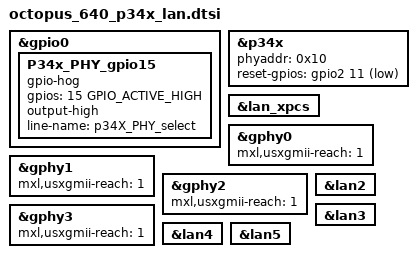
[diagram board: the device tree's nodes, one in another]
// SPDX-License-Identifier: GPL-2.0
/*
 * Copyright (C) 2024 MaxLinear, Inc.
 */

/* Select P34x */
&gpio0 {
	P34x_PHY_gpio15 {
		gpio-hog;
		gpios = <15 GPIO_ACTIVE_HIGH>;
		output-high;
		line-name = "p34X_PHY_select";
	};
};

/* P34x */
&p34x {
	status = "okay";
	phyaddr = <0x10>;
	reset-gpios = <&gpio2 11 GPIO_ACTIVE_LOW>; /* GPIO 75 */
};

&lan_xpcs {
	status = "okay";
};

&gphy0 {
	status = "okay";
	mxl,usxgmii-reach = <1>; /* 0(short), 1(medium), 2(long) */
};

&gphy1 {
	status = "okay";
	mxl,usxgmii-reach = <1>; /* 0(short), 1(medium), 2(long) */
};

&gphy2 {
	status = "okay";
	mxl,usxgmii-reach = <1>; /* 0(short), 1(medium), 2(long) */
};

&gphy3 {
	status = "okay";
	mxl,usxgmii-reach = <1>; /* 0(short), 1(medium), 2(long) */
};

&lan2 {
	status = "okay";
};

&lan3 {
	status = "okay";
};

&lan4 {
	status = "okay";
};

&lan5 {
	status = "okay";
};
